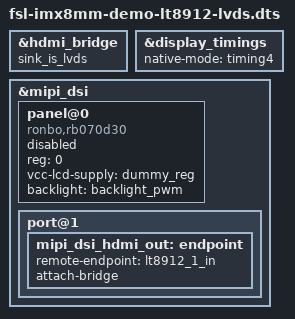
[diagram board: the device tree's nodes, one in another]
// SPDX-License-Identifier: (GPL-2.0+ OR MIT)
/*
 * Copyright 2019 NXP
 */

#include "fsl-imx8mm-demo.dts"

&hdmi_bridge {
	sink_is_lvds;
	status = "okay";
};

&display_timings {
	native-mode = <&timing4>;
};

&mipi_dsi {
    status = "okay";

    panel@0 {
        compatible = "ronbo,rb070d30";
        reg = <0>;
        vcc-lcd-supply = <&dummy_reg>;
        backlight = <&backlight_pwm>;
        status = "disabled";
    };

    port@1 {
        mipi_dsi_hdmi_out: endpoint {
            remote-endpoint = <&lt8912_1_in>;
            attach-bridge;
        };
    };
};
